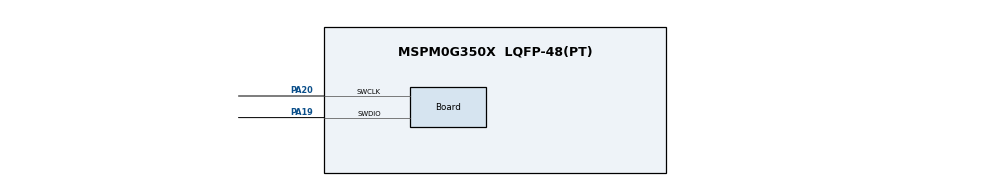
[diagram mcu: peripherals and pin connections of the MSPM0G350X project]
/**
 * @cliArgs --device "MSPM0G350X" --part "Default" --package "LQFP-48(PT)" --product "mspm0_sdk@2.04.00.06"
 * @versions {"tool":"1.22.0+3893"}
 */

/**
 * Import the modules used in this configuration.
 */
const GPIO    = scripting.addModule("/ti/driverlib/GPIO", {}, false);
const GPIO1   = GPIO.addInstance();
const GPIO2   = GPIO.addInstance();
const SYSCTL  = scripting.addModule("/ti/driverlib/SYSCTL");
const SYSTICK = scripting.addModule("/ti/driverlib/SYSTICK");

/**
 * Write custom configuration values to the imported modules.
 */
GPIO1.$name                          = "LED";
GPIO1.associatedPins[0].$name        = "PIN_14";
GPIO1.associatedPins[0].assignedPort = "PORTA";
GPIO1.associatedPins[0].assignedPin  = "13";

const Board                       = scripting.addModule("/ti/driverlib/Board", {}, false);
Board.peripheral.$assign          = "DEBUGSS";
Board.peripheral.swclkPin.$assign = "PA20";
Board.peripheral.swdioPin.$assign = "PA19";

GPIO2.port                               = "PORTA";
GPIO2.$name                              = "KEY";
GPIO2.associatedPins[0].direction        = "INPUT";
GPIO2.associatedPins[0].polarity         = "RISE";
GPIO2.associatedPins[0].internalResistor = "PULL_DOWN";
GPIO2.associatedPins[0].interruptEn      = true;
GPIO2.associatedPins[0].$name            = "PIN_18";
GPIO2.associatedPins[0].assignedPin      = "12";

SYSCTL.forceDefaultClkConfig = true;
SYSCTL.peripheral.$assign    = "SYSCTL";

SYSTICK.periodEnable      = true;
SYSTICK.period            = 32000;
SYSTICK.interruptEnable   = true;
SYSTICK.systickEnable     = true;
SYSTICK.interruptPriority = "0";

const ProjectConfig              = scripting.addModule("/ti/project_config/ProjectConfig", {}, false);
ProjectConfig.migrationCondition = true;

/**
 * Pinmux solution for unlocked pins/peripherals. This ensures that minor changes to the automatic solver in a future
 * version of the tool will not impact the pinmux you originally saw.  These lines can be completely deleted in order to
 * re-solve from scratch.
 */
GPIO1.associatedPins[0].pin.$suggestSolution = "PA13";
GPIO2.associatedPins[0].pin.$suggestSolution = "PA12";
